AUTOSAR XML (schema 4-0-3)
package /ComponentTypes
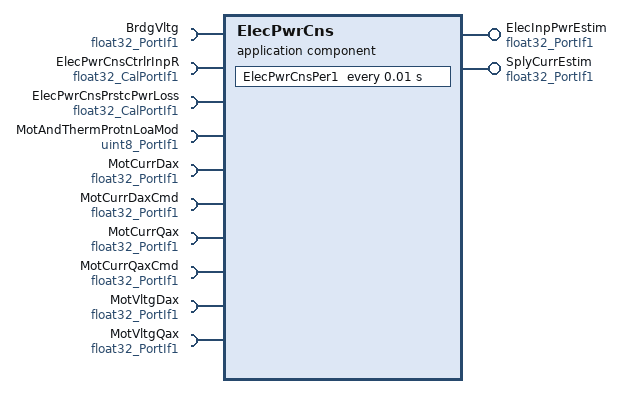
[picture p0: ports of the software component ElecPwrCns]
  application sw component type ElecPwrCns
    provide port ElecInpPwrEstim: nonqueued-sender-com-spec{data-element=Val, init-value=0}, provided-interface=float32_PortIf1
    provide port SplyCurrEstim: nonqueued-sender-com-spec{data-element=Val, init-value=0}, provided-interface=float32_PortIf1
    10 x require port:
      BrdgVltg: nonqueued-receiver-com-spec{data-element=Val, filter=data-filter-type=ALWAYS, init-value=6}, required-interface=float32_PortIf1
      ElecPwrCnsCtrlrInpR: parameter-require-com-spec{init-value=0.0005, parameter=Val}, required-interface=float32_CalPortIf1
      ElecPwrCnsPrstcPwrLoss: parameter-require-com-spec{init-value=10, parameter=Val}, required-interface=float32_CalPortIf1
      MotAndThermProtnLoaMod: nonqueued-receiver-com-spec{data-element=Val, filter=data-filter-type=ALWAYS, init-value=0}, required-interface=uint8_PortIf1
      MotCurrDax: nonqueued-receiver-com-spec{data-element=Val, filter=data-filter-type=ALWAYS, init-value=0}, required-interface=float32_PortIf1
      MotCurrDaxCmd: nonqueued-receiver-com-spec{data-element=Val, filter=data-filter-type=ALWAYS, init-value=0}, required-interface=float32_PortIf1
      MotCurrQax: nonqueued-receiver-com-spec{data-element=Val, filter=data-filter-type=ALWAYS, init-value=0}, required-interface=float32_PortIf1
      MotCurrQaxCmd: nonqueued-receiver-com-spec{data-element=Val, filter=data-filter-type=ALWAYS, init-value=0}, required-interface=float32_PortIf1
      MotVltgDax: nonqueued-receiver-com-spec{data-element=Val, filter=data-filter-type=ALWAYS, init-value=0}, required-interface=float32_PortIf1
      MotVltgQax: nonqueued-receiver-com-spec{data-element=Val, filter=data-filter-type=ALWAYS, init-value=0}, required-interface=float32_PortIf1
    behavior ElecPwrCns_InternalBehavior
      ar-typed-per-instance-memorys:
        4 x data, all with sw-calibration-access=READ-ONLY, type=float32:
          dElecPwrCnsDrpInpPwr
          dElecPwrCnsModInpPwr
          dElecPwrCnsMotCurrDaxEstim
          dElecPwrCnsMotCurrQaxEstim
      timing event TMT_ElecPwrCnsPer1: start-on-event=ElecPwrCnsPer1, period=0.01
      runnable ElecPwrCnsPer1
        data-receive-point-by-arguments:
          8 x access:
            REC_BrdgVltg_Val: accessed-variable=BrdgVltg.Val
            REC_MotAndThermProtnLoaMod_Val: accessed-variable=MotAndThermProtnLoaMod.Val
            REC_MotCtrlMotCurrDax_Val: accessed-variable=MotCurrDax.Val
            REC_MotCtrlMotCurrQax_Val: accessed-variable=MotCurrQax.Val
            REC_MotCtrlMotVltgDax_Val: accessed-variable=MotVltgDax.Val
            REC_MotCtrlMotVltgQax_Val: accessed-variable=MotVltgQax.Val
            REC_MotCurrDaxCmd_Val: accessed-variable=MotCurrDaxCmd.Val
            REC_MotCurrQaxCmd_Val: accessed-variable=MotCurrQaxCmd.Val
        data-send-points:
          access SEND_ElecInpPwrEstim_Val: accessed-variable=ElecInpPwrEstim.Val
          access SEND_SplyCurrEstim_Val: accessed-variable=SplyCurrEstim.Val
  swc implementation ElecPwrCns_Implementation: behavior=ElecPwrCns_InternalBehavior
    code-descriptors:
      code Default: artifact-descriptors=autosar-engineering-object={short-label=Default, category=SWSRC}
